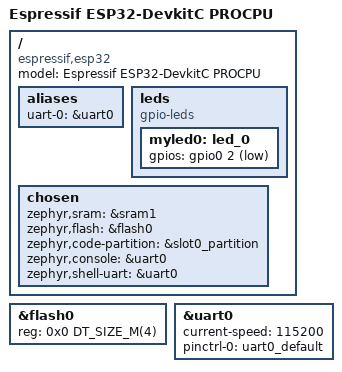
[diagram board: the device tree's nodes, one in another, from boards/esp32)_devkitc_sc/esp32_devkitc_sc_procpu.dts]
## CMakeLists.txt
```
cmake_minimum_required(VERSION 3.20.0)

set(EXTRA_DTC_OVERLAY_FILE ${CMAKE_CURRENT_SOURCE_DIR}/app.overlay)

list(APPEND BOARD_ROOT ${CMAKE_CURRENT_SOURCE_DIR})

find_package(Zephyr REQUIRED HINTS $ENV{ZEPHYR_BASE})
project(my_zephyr_app)

target_sources(app PRIVATE src/main.cpp src/board.c src/shell_cmds.c)
add_subdirectory(drivers/trfx/mau)

target_include_directories(app PRIVATE include)
```

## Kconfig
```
menu "LED Subsystem"

config APP_HEARTBEAT_PERIOD_MS
 int "Heartbeat period(ms)"
 default 500
 range 100 2000

choice BLINK_SLEEP
 prompt "LED blink sleep time"
 default BLINK_SLEEP_250MS

config BLINK_SLEEP_250MS
bool "Fast (250ms)"

config BLINK_SLEEP_1000MS
bool "Medium (1s)"

config BLINK_SLEEP_2000MS
bool "Slow (2s)"

endchoice

menu "Advanced LED Settings"
    config LED_BRIGHTNESS
    int "LED brightness"
    default 100
    range 0 100

    config LED_FADE_DURATION
    int "LED Fade Duration (ms)"
    default 500

    menu "Expert Settings"
        config LED_DEBUGGING
        bool "Enable LED debugging"

        config LED_CUSTOM_BLINK
        bool "Custom blink pattern"
    endmenu
endmenu

endmenu

source "Kconfig.zephyr"
rsource "drivers/trfx/mau/Kconfig"
```

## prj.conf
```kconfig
CONFIG_GPIO=y
CONFIG_LOG=y
CONFIG_MAU_CUSTOM_DRIVED=y
CONFIG_SHELL=y
CONFIG_SHELL_CMDS=y
CONFIG_SHELL_TAB=y
CONFIG_SHELL_TAB_AUTOCOMPLETION=y
CONFIG_SHELL_HISTORY=y
CONFIG_SHELL_LOG_BACKEND=y
CONFIG_SHELL_BACKEND_SERIAL=y
```

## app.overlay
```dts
/ {

    aliases {
        app-led = &myled0;
    };
};
```

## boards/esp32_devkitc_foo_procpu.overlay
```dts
/ {
    leds {
        compatible = "gpio-leds";

        myled0: led_0 {
            gpios = <&gpio0 2 GPIO_ACTIVE_LOW>;
        };
    };

    mau0: mau {
        compatible = "mau";
        status = "okay";
    };
};
```

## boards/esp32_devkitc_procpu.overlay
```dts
/ {

    aliases {
        led0 = &myled0;
    };

    leds {
        compatible = "gpio-leds";

        myled0: led_0 {
            gpios = <&gpio0 2 GPIO_ACTIVE_LOW>;
        };
    };
};
```

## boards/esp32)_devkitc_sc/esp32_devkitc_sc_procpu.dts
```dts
/*
 * Copyright (c) 2023-2025 Espressif Systems (Shanghai) Co., Ltd.
 *
 * SPDX-License-Identifier: Apache-2.0
 */
/dts-v1/;

#include <espressif/esp32/esp32.dtsi>
#include "esp32_devkitc-pinctrl.dtsi"
#include <zephyr/dt-bindings/input/input-event-codes.h>
#include <espressif/partitions_0x1000_amp.dtsi>

/ {
	model = "Espressif ESP32-DevkitC PROCPU";
	compatible = "espressif,esp32";


	aliases {
		uart-0 = &uart0;
	};

    leds {
        compatible = "gpio-leds";

        myled0: led_0 {
            gpios = <&gpio0 2 GPIO_ACTIVE_LOW>;
        };
    };

	chosen {
		zephyr,sram = &sram1;
		zephyr,flash = &flash0;
		zephyr,code-partition = &slot0_partition;
		zephyr,console = &uart0;
		zephyr,shell-uart = &uart0;
	};
};

&flash0 {
	reg = <0x0 DT_SIZE_M(4)>;
	ranges = <0x0 0x0 DT_SIZE_M(4)>;
};

&uart0 {
	status = "okay";
	current-speed = <115200>;
	pinctrl-0 = <&uart0_default>;
	pinctrl-names = "default";
};
```

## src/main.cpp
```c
#include "zephyr/device.h"
#include "zephyr/drivers/sensor.h"
#include "zephyr/sleep.h"
#include "zephyr/sys/printk.h"
#include <zephyr/drivers/gpio.h>
#include <zephyr/kernel.h>
#include <zephyr/logging/log.h>
#include "trfx_mau.h"

#define SLEEP_TIME_MS 1000

/* The devicetree node identifier for the "led0" alias. */
#define LED_NODE DT_ALIAS(app_led)

#if !DT_NODE_HAS_STATUS(LED_NODE, okay)
#error "Missing `app_led` alias in devicetree"
#endif

static const struct gpio_dt_spec led = GPIO_DT_SPEC_GET(LED_NODE, gpios);
const struct device *dev = DEVICE_DT_GET_ANY(mau);
struct sensor_value sv = {
	.val1 = 1,
	.val2 = 2,
};

LOG_MODULE_REGISTER(main, LOG_LEVEL_INF);
int main(void)
{
	bool led_state = true;

	if (!gpio_is_ready_dt(&led)) {
		return 0;
	}

	if (gpio_pin_configure_dt(&led, GPIO_OUTPUT_ACTIVE) < 0) {
		return 0;
	}

	if (!(device_is_ready(dev))) {
		return 0;
	}

	while (1) {

		// on
		if (!led_state && sensor_sample_fetch(dev) == 0) {
			gpio_pin_set_dt(&led, 1);
			trfx_mau_set_counter(dev, 100);
		}

		// off
		if (led_state &&
		    sensor_channel_get(dev, SENSOR_CHAN_GAUGE_STATE_OF_HEALTH, &sv) == 0) {
			gpio_pin_set_dt(&led, 0);
			trfx_mau_set_counter(dev, 200);
		}
		// if (gpio_pin_toggle_dt(&led) < 0) {
		// 	return 0;
		// }

		led_state = !led_state;
		printk("LED state: %s\n", led_state ? "ON" : "OFF");
		// k_msleep(SLEEP_TIME_MS);
		k_msleep(CONFIG_APP_HEARTBEAT_PERIOD_MS);
	}
	return 0;
}
```

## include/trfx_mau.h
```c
#ifndef TRFX_MAU_H
#define TRFX_MAU_H

#include <zephyr/device.h>

#ifdef __cplusplus
extern "C" {
#endif

int trfx_mau_set_counter(const struct device *dev, int value);

#ifdef __cplusplus
}
#endif

#endif
```

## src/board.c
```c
#include<zephyr/init.h>
#include<zephyr/kernel.h>

static int board_esp32_devkitc_sc_procpu_init(void) {
    printk("HELLO\n");
    return 0;
}
SYS_INIT(board_esp32_devkitc_sc_procpu_init, PRE_KERNEL_1, 0);
```

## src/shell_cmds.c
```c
#include <zephyr/shell/shell.h>
#include <stdlib.h>
#include <errno.h>
#include <limits.h>

static int info(const struct shell *sh, size_t argc, char **argv)
{
	shell_print(sh, "App version: 1.0.0; ESP32 WROOM DEVKIT-1");
	return 0;
};
static int get(const struct shell *sh, size_t argc, char **argv)
{
	shell_print(sh, "App version: 1.0.0");
	return 0;
};
// SHELL_CMD_REGISTER(info, NULL, "Show app version", info);
static int sensor_set_value(const struct shell *sh, size_t argc, char **argv)
{

    // argv[0] = "set"
    // argv[1] = "<value>"

	if (argc != 2) {
		shell_error(sh, "Usage: set <value>  must have exactly 1 argument");
		return -EINVAL;
	}

	char *endptr;
    errno = 0;

    long value = strtol(argv[1], &endptr, 10);

    if (errno == ERANGE || *argv[1] == '\0' ||
        *endptr != '\0' ||
        value < INT_MIN || value > INT_MAX) {
        shell_error(sh, "Argument must be an integer");
        return -EINVAL;
    }

    int number = (int)value;

	shell_print(sh, "WTF???? %d", number);
	return 0;
};
SHELL_STATIC_SUBCMD_SET_CREATE(sub_sensor_set,
    SHELL_CMD_ARG(set, NULL, "Set sensor value", sensor_set_value, 2, 0),
    SHELL_SUBCMD_SET_END,
);

SHELL_CMD_REGISTER(sensor, &sub_sensor_set, "Sensor commands", NULL);
```
